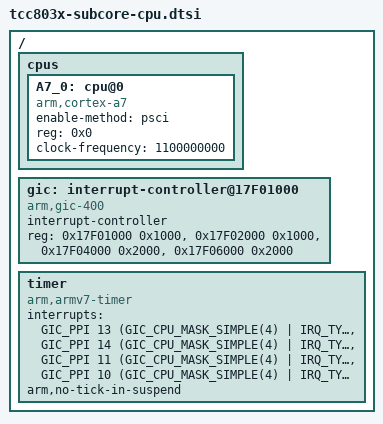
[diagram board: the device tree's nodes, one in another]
// SPDX-License-Identifier: (GPL-2.0-or-later OR MIT)
/*
 * Copyright (C) 2023 Telechips Inc.
 */

#include <dt-bindings/interrupt-controller/arm-gic.h>

/ {
	cpus: cpus {
		#address-cells = <1>;
		#size-cells = <0>;

		A7_0: cpu@0 {
			device_type = "cpu";
			compatible = "arm,cortex-a7";
			enable-method = "psci";
			reg = <0x0>;
			clock-frequency = <1100000000>;
		};
	};

	gic: interrupt-controller@17F01000 {
		compatible = "arm,gic-400";
		#interrupt-cells = <3>;
		#address-cells = <0>;
		interrupt-controller;
		reg = <0x17F01000 0x1000>,
		      <0x17F02000 0x1000>,
		      <0x17F04000 0x2000>,
		      <0x17F06000 0x2000>;
	};

	timer: timer {
		compatible = "arm,armv7-timer";
		interrupts = <GIC_PPI 13 (GIC_CPU_MASK_SIMPLE(4) | IRQ_TYPE_LEVEL_LOW)>,
			     <GIC_PPI 14 (GIC_CPU_MASK_SIMPLE(4) | IRQ_TYPE_LEVEL_LOW)>,
			     <GIC_PPI 11 (GIC_CPU_MASK_SIMPLE(4) | IRQ_TYPE_LEVEL_LOW)>,
			     <GIC_PPI 10 (GIC_CPU_MASK_SIMPLE(4) | IRQ_TYPE_LEVEL_LOW)>;

		arm,no-tick-in-suspend;
	};
};
